# Template register map
Vendor: VendorName Co.Ltd; Series: SeriesName; File version: 1.2
CPU: CM7 r0p1, little endian, MPU, FPU, 4 interrupt priority bits
Registers are 32-bit, read-write, no defined reset value unless marked. A register's access mark holds for its fields unless they carry their own. Offsets are from the block's base; [hi:lo] are bit positions; lines under a group give offsets from that group; {n}, {i} and the like mark numbered series.

## GPIOA — General-Purpose Input Or Output A
Base 0x400A0000
Same registers: GPIOB 0x400A0400, GPIOC 0x400A0800, GPIOD 0x400A0C00, GPIOE 0x400A1000, GPIOF 0x400A1400, GPIOG 0x400A1800, GPIOH 0x400A1C00
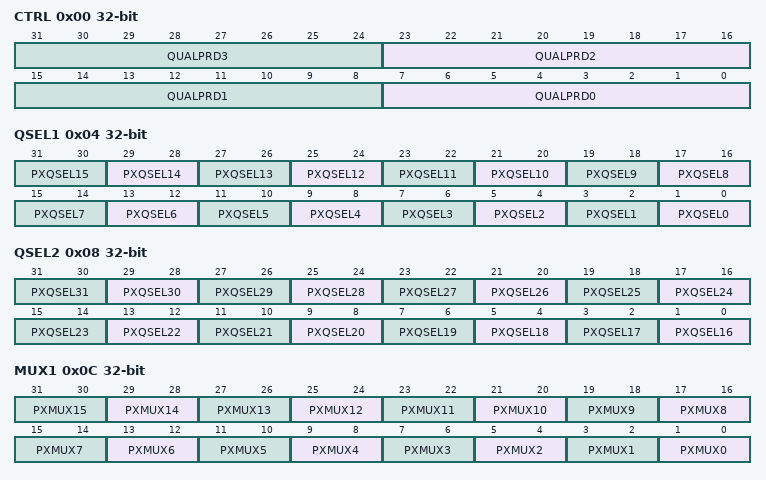
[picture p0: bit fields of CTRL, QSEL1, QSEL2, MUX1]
0x00 CTRL — GPIO sampling period control register
  [8n+7:8n] QUALPRD{n} (n=0..3) — GPIOA QUALPRD{n}[7:0] bit: qualification sampling period for GPIO{8n} to GPIO{8n+7}
0x04 QSEL1 — GPIO input sampling select register 1
  [2n+1:2n] PXQSEL{n} (n=0..15) — GPIOA PXQSEL{n}[1:0] bit: select input qualification type for GPIO{n}
0x08 QSEL2 — GPIO input sampling select register 2
  [2n-31:2n-32] PXQSEL{n} (n=16..31) — GPIOA PXQSEL{n}[1:0] bit: select input qualification type for GPIO{n}
0x0C MUX1 — GPIO multiplexing function register 1
  [2n+1:2n] PXMUX{n} (n=0..15) — GPIOA PXMUX{n}[1:0] bit: pin-muxing selection for GPIO{n}
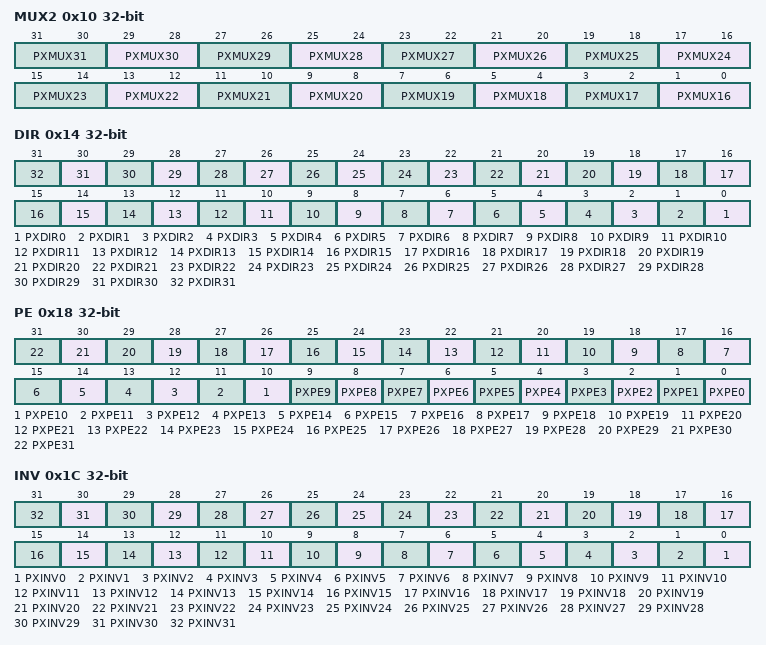
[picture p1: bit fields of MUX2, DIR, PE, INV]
0x10 MUX2 — GPIO multiplexing function register 2
  [2n-31:2n-32] PXMUX{n} (n=16..31) — GPIOA PXMUX{n}[1:0] bit: pin-muxing selection for GPIO{n}
0x14 DIR — GPIO direction register
  [n] PXDIR{n} (n=0..31) — GPIOA PXDIR{n} bit: direction for GPIO{n}
0x18 PE — GPIO pull-up/down enable register
  [n] PXPE{n} (n=0..31) — GPIOA PXPE{n} bit: pull-up/down enable for GPIO{n}
0x1C INV — GPIO input polarity invert register
  [n] PXINV{n} (n=0..31) — GPIOA PXINV{n} bit: input inversion control for GPIO{n}
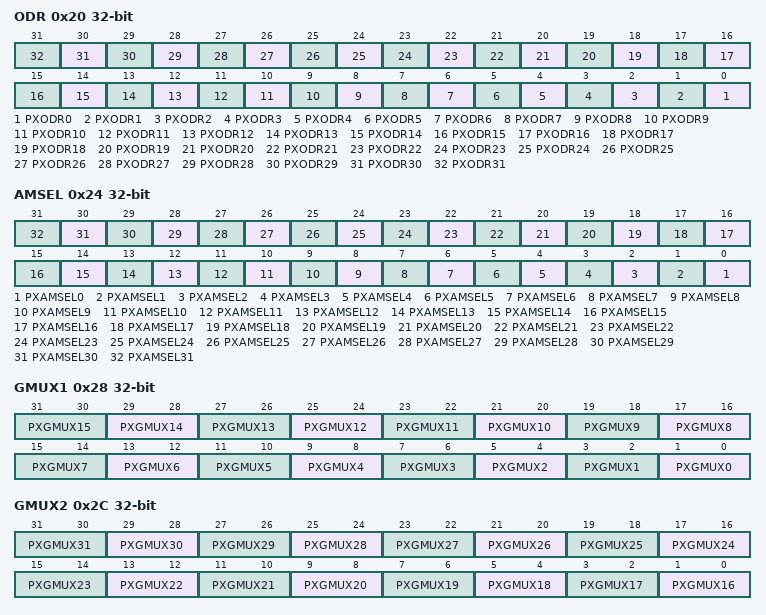
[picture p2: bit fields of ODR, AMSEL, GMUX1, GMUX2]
0x20 ODR — GPIO open-drain output register
  [n] PXODR{n} (n=0..31) — GPIOA PXODR{n} bit: outpout open-drain control for GPIO{n}
0x24 AMSEL — GPIO analog mode select register
  [n] PXAMSEL{n} (n=0..31) — GPIOA PXAMSEL{n} bit: analog mode select for GPIO{n}
0x28 GMUX1 — GPIO multiplexing group register 1
  [2n+1:2n] PXGMUX{n} (n=0..15) — GPIOA PXGMUX{n}[1:0] bit: pin-muxing selection for GPIO{n}
0x2C GMUX2 — GPIO multiplexing group register 2
  [2n-31:2n-32] PXGMUX{n} (n=16..31) — GPIOA PXGMUX{n}[1:0] bit: pin-muxing selection for GPIO{n}
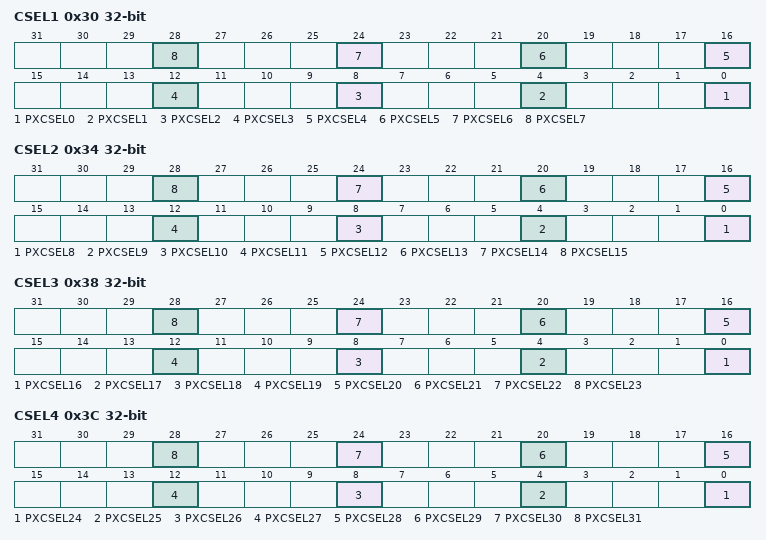
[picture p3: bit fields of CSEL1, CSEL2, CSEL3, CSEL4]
0x30 CSEL1 — GPIO selected with CPU register 1
  [4n] PXCSEL{n} (n=0..7) — GPIOA PXCSEL{n} bit: selects which master's registers control GPIO{n}
0x34 CSEL2 — GPIO selected with CPU register 2
  [4n-32] PXCSEL{n} (n=8..15) — GPIOA PXCSEL{n} bit: selects which master's registers control GPIO{n}
0x38 CSEL3 — GPIO selected with CPU register 3
  [4n-64] PXCSEL{n} (n=16..23) — GPIOA PXCSEL{n} bit: selects which master's registers control GPIO{n}
0x3C CSEL4 — GPIO selected with CPU register 4
  [4n-96] PXCSEL{n} (n=24..31) — GPIOA PXCSEL{n} bit: selects which master's registers control GPIO{n}
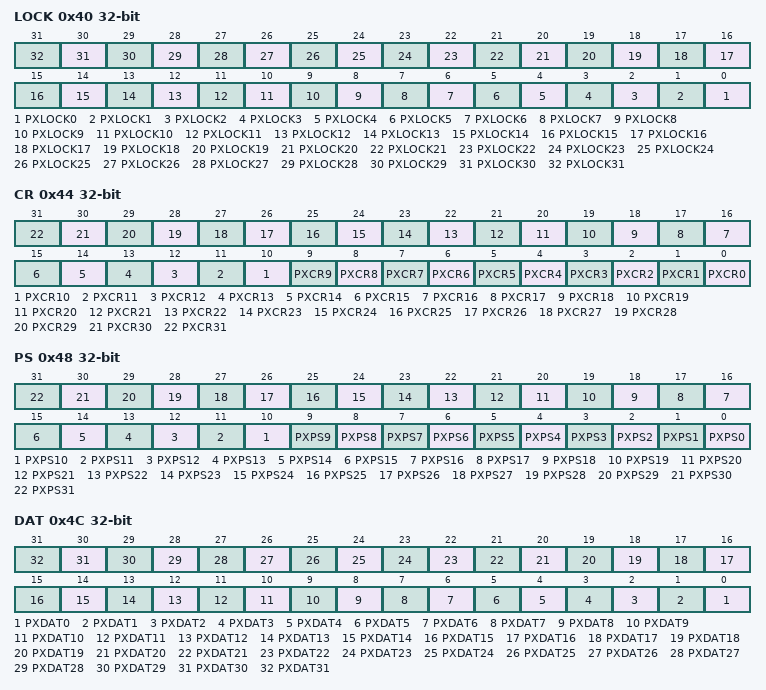
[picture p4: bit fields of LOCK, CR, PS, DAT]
0x40 LOCK — GPIO locker register
  [n] PXLOCK{n} (n=0..31) — GPIOA PXLOCK{n} bit: configuration lock bit for GPIO{n}
0x44 CR — GPIO locker control register
  [n] PXCR{n} (n=0..31) — GPIOA PXCR{n} bit: configuration lock commit bit for GPIO{n}
0x48 PS — GPIO pull-up/down selection register
  [n] PXPS{n} (n=0..31) — GPIOA PXPS{n} bit: pull-up/down selection for GPIO{n}
0x4C DAT — GPIO data register
  [n] PXDAT{n} (n=0..31) — GPIOA PXDAT{n} bit: data register for GPIO{n}
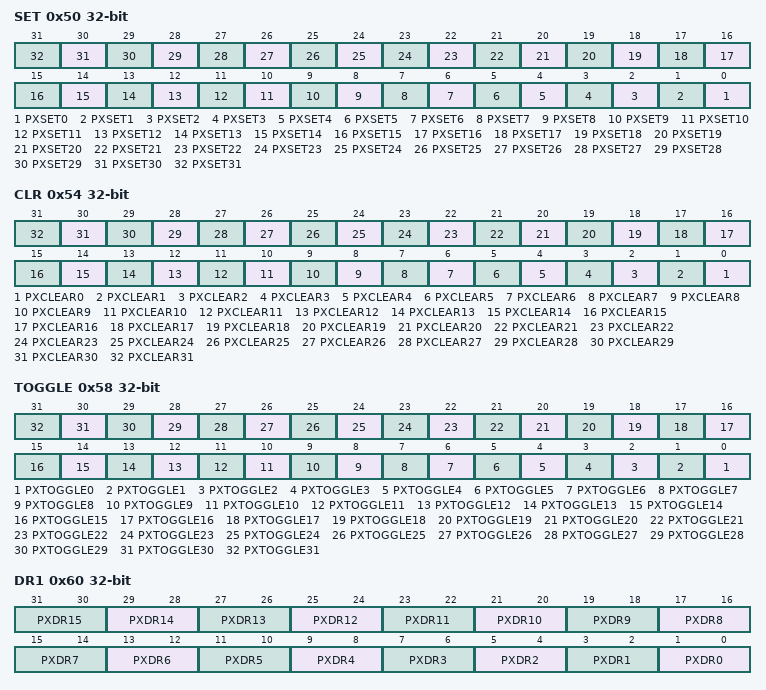
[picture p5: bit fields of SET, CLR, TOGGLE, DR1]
0x50 SET — GPIO set data register
  [n] PXSET{n} (n=0..31) — GPIOA PXSET{n} bit: output set bit for GPIO{n}
0x54 CLR — GPIO clear data register
  [n] PXCLEAR{n} (n=0..31) — GPIOA PXCLEAR{n} bit: output clear bit for GPIO{n}
0x58 TOGGLE — GPIO toggle data register
  [n] PXTOGGLE{n} (n=0..31) — GPIOA PXTOGGLE{n} bit: output toggle register for GPIO{n}
0x5C DATR ro — GPIO read data register
  [31:0] DATA — GPIOA DATA[31:0] bit: a read from this register returns the contents of GPADAT register
0x60 DR1 — GPIO driver register 1
  [2n+1:2n] PXDR{n} (n=0..15) — GPIOA PXDR{n}[1:0] bit: driving force selection for GPIO{n}
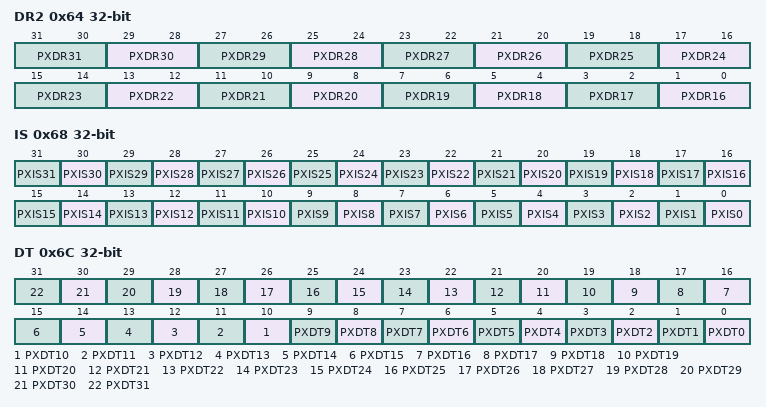
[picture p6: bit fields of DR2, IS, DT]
0x64 DR2 — GPIO driver register 2
  [2n-31:2n-32] PXDR{n} (n=16..31) — GPIOA PXDR{n}[1:0] bit: driving force selection for GPIO{n}
0x68 IS — GPIO schmidt trigger seletion register
  [n] PXIS{n} (n=0..31) — GPIOA PXIS{n} bit: schmidt input trigger seletion for GPIO{n}
0x6C DT — GPIO waveform shaping register
  [n] PXDT{n} (n=0..31) — GPIOA PXDT{n} bit: output waveform shaping selection for GPIO{n}
